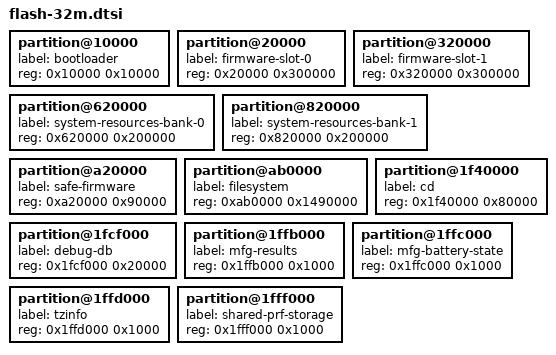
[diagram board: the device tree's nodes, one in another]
// SPDX-FileCopyrightText: 2026 Core Devices LLC
// SPDX-License-Identifier: Apache-2.0

// The firmware partitions of the 32 MiB flash, around the ptable and mfg-info
// partitions of the board.

partition@10000 {
	label = "bootloader";
	reg = <0x10000 0x10000>;
};

partition@20000 {
	label = "firmware-slot-0";
	reg = <0x20000 0x300000>;
};

partition@320000 {
	label = "firmware-slot-1";
	reg = <0x320000 0x300000>;
};

partition@620000 {
	label = "system-resources-bank-0";
	reg = <0x620000 0x200000>;
};

partition@820000 {
	label = "system-resources-bank-1";
	reg = <0x820000 0x200000>;
};

partition@a20000 {
	label = "safe-firmware";
	reg = <0xa20000 0x90000>;
};

partition@ab0000 {
	label = "filesystem";
	reg = <0xab0000 0x1490000>;
};

partition@1f40000 {
	label = "cd";
	reg = <0x1f40000 0x80000>;
};

partition@1fcf000 {
	label = "debug-db";
	reg = <0x1fcf000 0x20000>;
};

partition@1ffb000 {
	label = "mfg-results";
	reg = <0x1ffb000 0x1000>;
};

partition@1ffc000 {
	label = "mfg-battery-state";
	reg = <0x1ffc000 0x1000>;
};

partition@1ffd000 {
	label = "tzinfo";
	reg = <0x1ffd000 0x1000>;
};

partition@1fff000 {
	label = "shared-prf-storage";
	reg = <0x1fff000 0x1000>;
};
